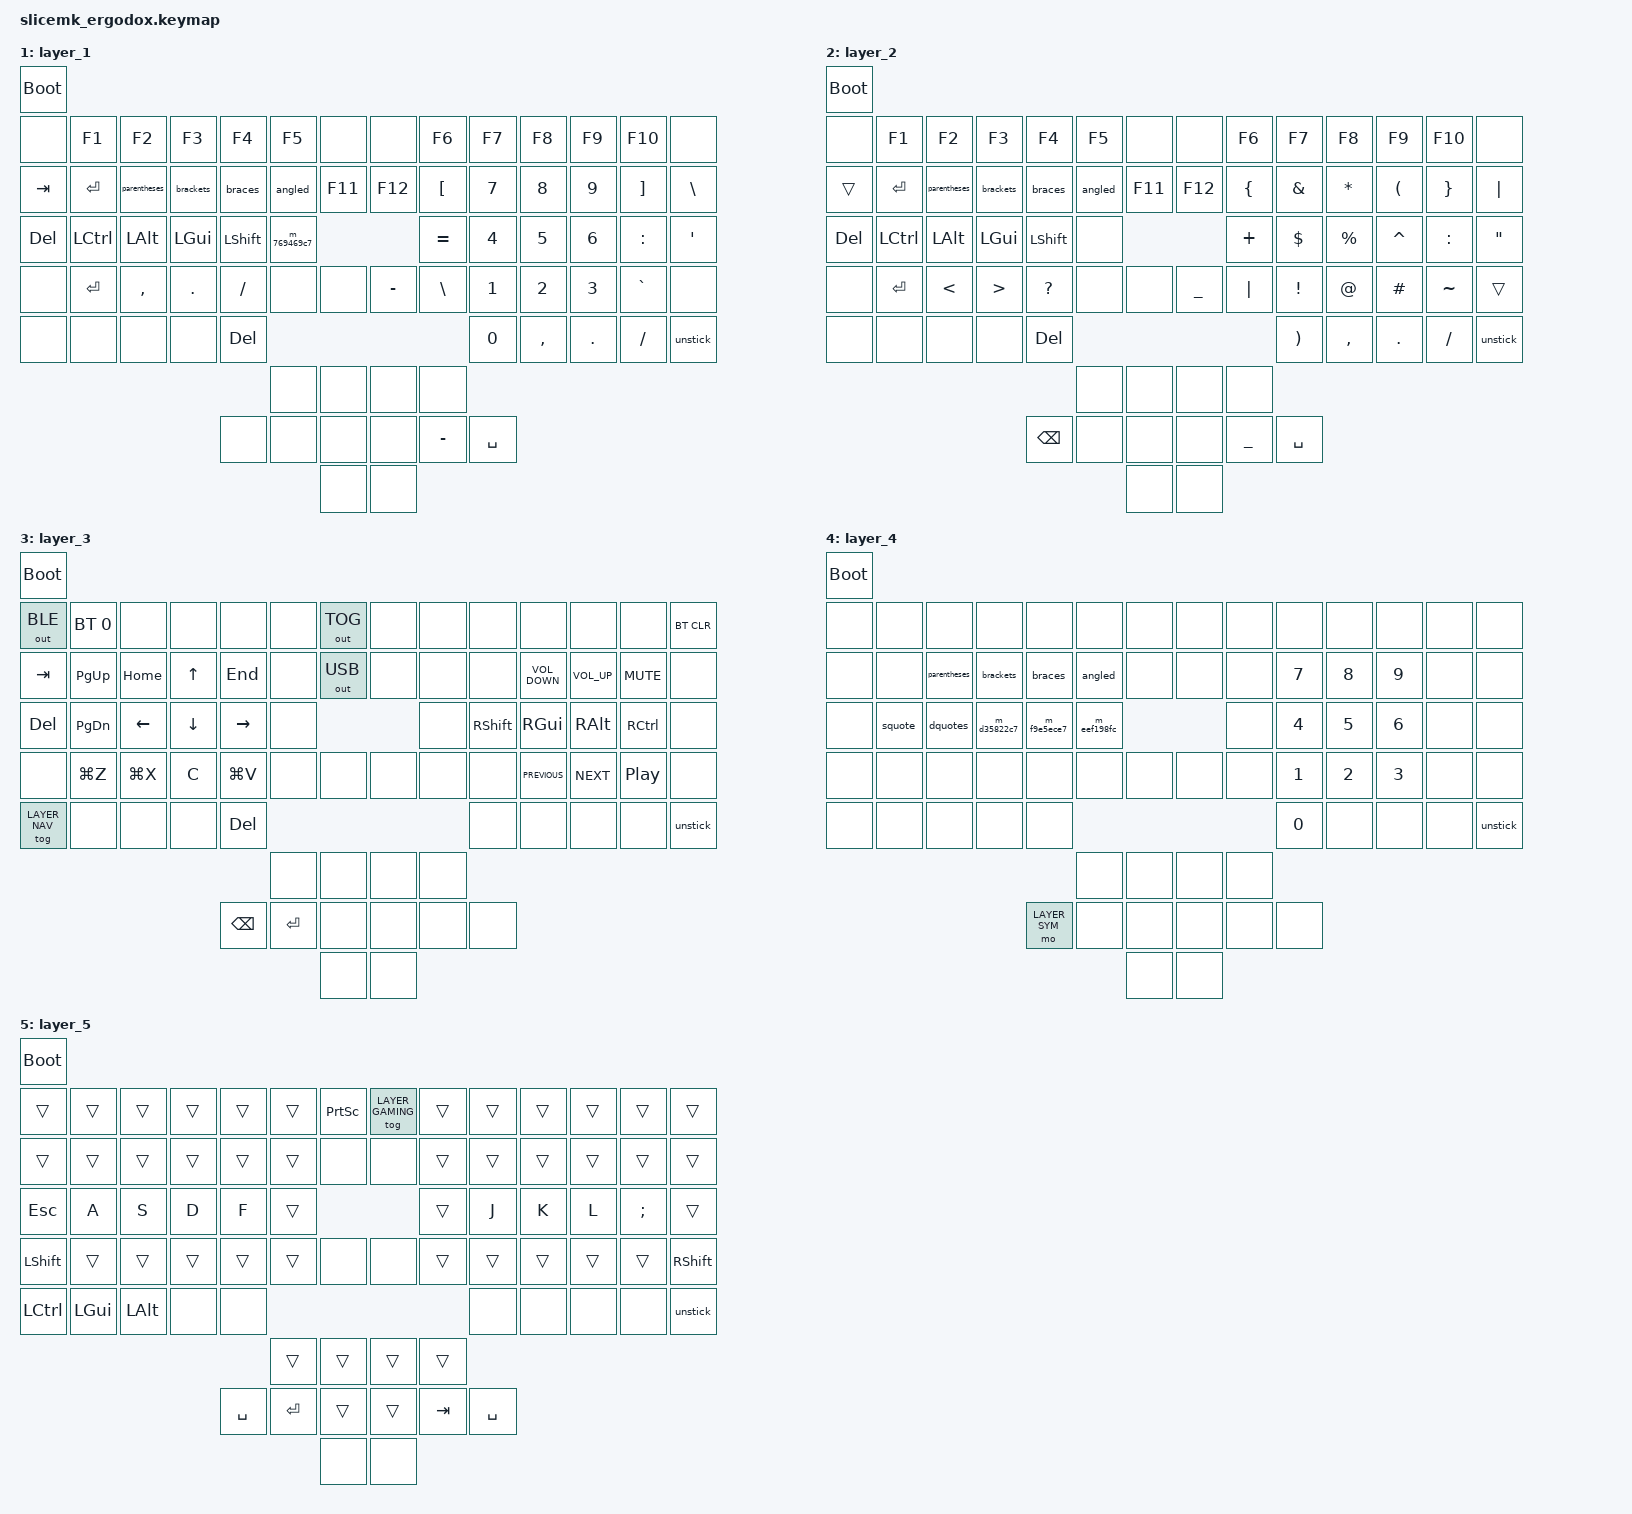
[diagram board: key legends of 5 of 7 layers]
#include <behaviors.dtsi>
#include <dt-bindings/zmk/bt.h>
#include <dt-bindings/zmk/keys.h>
#include <dt-bindings/zmk/outputs.h>
#include <dt-bindings/zmk/rgb.h>

#define LAYER_MAIN 0
#define LAYER_SYM 1
#define LAYER_SHIFTSYM 2
#define LAYER_NAV 3
#define LAYER_MACROS 4
#define LAYER_GAMING 5
#define LAYER_LINUX 6

&mt {
    tapping-term-ms = <200>;
	flavor = "tap-preferred";
	quick-tap-ms = <0>;
};

&lt {
    tapping-term-ms = <200>;
	flavor = "tap-preferred";
	quick-tap-ms = <0>;
};

&sk {
	quick-release;
};

/ {
	ZMK_MACRO(brackets, 
		wait-ms = <0>;
		tap-ms = <0>;
		bindings = <&kp LBKT &kp RBKT &kp LEFT>;
	)

	ZMK_MACRO(parentheses, 
		wait-ms = <0>;
		tap-ms = <0>;
		bindings = <&kp LPAR &kp RPAR &kp LEFT>;
	)

	ZMK_MACRO(braces, 
		wait-ms = <0>;
		tap-ms = <0>;
		bindings = <&kp LBRC &kp RBRC &kp LEFT>;
	)

	ZMK_MACRO(angled, 
		wait-ms = <0>;
		tap-ms = <0>;
		bindings = <&kp LT &kp GT &kp LEFT>;
	)

	ZMK_MACRO(squote, 
		wait-ms = <0>;
		tap-ms = <0>;
		bindings = <&kp SINGLE_QUOTE &kp SINGLE_QUOTE &kp LEFT>;
	)

	ZMK_MACRO(dquotes, 
		wait-ms = <0>;
		tap-ms = <0>;
		bindings = <&kp DOUBLE_QUOTES &kp DOUBLE_QUOTES &kp LEFT>;
	)

	ZMK_MACRO(unstick,
		wait-ms = <0>;
		tap-ms = <0>;
		bindings = <&kp LSHIFT &kp RSHIFT &kp LCTRL &kp RCTRL &kp LALT &kp RALT &kp LGUI &kp RGUI &to LAYER_MAIN>;
	)

	ZMK_MACRO(caps_macro,
		tap-ms = <200>;
		bindings = <&kp CAPS>;
	)

	sc: shift_caps {
		label = "shift caps";
		compatible = "zmk,behavior-hold-tap";
		#binding-cells = <2>;
		tapping-term-ms = <200>;
		flavor = "hold-preferred";
		bindings = <&kp>, <&caps_macro>;
	};

};


/ {
	keymap {
		compatible = "zmk,keymap";
		layer_0 {
			bindings = <
				&bootloader
				&kp GRAVE      &kp NUMBER_1       &kp NUMBER_2   &kp NUMBER_3   &kp NUMBER_4            &kp NUMBER_5              &mt LS(LG(NUMBER_4)) LS(LC(LG(NUMBER_4))) &tog LAYER_GAMING &kp NUMBER_6         &kp NUMBER_7        &kp NUMBER_8    &kp NUMBER_9     &kp NUMBER_0                &kp BACKSPACE
				&kp TAB        &kp Q              &kp W          &kp E          &kp R                   &kp T                     &kp LG(SPACE)                             &kp RC(RG(SPACE)) &kp Y                &kp U               &kp I           &kp O            &kp P                       &kp BACKSLASH
				&kp ESCAPE     &mt LEFT_CONTROL A &mt LEFT_ALT S &mt LEFT_GUI D &mt LEFT_SHIFT F        &kp G                                                                                 &kp H                &mt RIGHT_SHIFT J   &mt RIGHT_GUI K &mt RIGHT_ALT L  &mt RIGHT_CONTROL SEMICOLON &kp SINGLE_QUOTE
				&caps_word     &kp Z              &kp X          &kp C          &kp V                   &kp B                     &kp EQUAL                                 &kp MINUS         &kp N                &kp M               &kp COMMA       &kp PERIOD       &kp SLASH                   &sk RIGHT_SHIFT
				&tog LAYER_NAV &kp LG(EQUAL)      &kp LG(MINUS)  &kp LEFT_GUI   &mt LC(LEFT_ALT) DELETE                                                                                                            &kp CAPSLOCK        &none           &tog LAYER_LINUX &none                       &unstick
				                                                                                        &kp C_PREVIOUS            &kp C_NEXT                                &kp C_VOLUME_DOWN &kp C_VOLUME_UP
				                                                                &lt LAYER_SYM BACKSPACE &lt LAYER_SHIFTSYM RETURN &kp C_PLAY_PAUSE                          &kp C_MUTE        &lt LAYER_MACROS TAB &lt LAYER_NAV SPACE
				                                                                                                                  &kp SPACE                                 &tog LAYER_SYM
			>;
		};
		layer_1 {
			bindings = <
				&bootloader
				&none      &kp F1           &kp F2       &kp F3       &kp F4         &kp F5      &none   &none     &kp F6           &kp F7       &kp F8       &kp F9       &kp F10           &none
				&kp TAB    &kp RETURN       &parentheses &brackets    &braces        &angled     &kp F11 &kp F12   &kp LEFT_BRACKET &kp NUMBER_7 &kp NUMBER_8 &kp NUMBER_9 &kp RIGHT_BRACKET &kp BACKSLASH
				&kp DELETE &kp LEFT_CONTROL &kp LEFT_ALT &kp LEFT_GUI &kp LEFT_SHIFT &m_769469c7                   &kp EQUAL        &kp NUMBER_4 &kp NUMBER_5 &kp NUMBER_6 &kp COLON         &kp SINGLE_QUOTE
				&none      &kp RETURN       &kp COMMA    &kp PERIOD   &kp SLASH      &none       &none   &kp MINUS &kp BACKSLASH    &kp NUMBER_1 &kp NUMBER_2 &kp NUMBER_3 &kp GRAVE         &none
				&none      &none            &none        &none        &kp DELETE                                                    &kp NUMBER_0 &kp COMMA    &kp PERIOD   &kp SLASH         &unstick
				                                                                     &none       &none   &none     &none
				                                                      &none          &none       &none   &none     &kp MINUS        &kp SPACE
				                                                                                 &none   &none
			>;
		};
		layer_2 {
			bindings = <
				&bootloader
				&none      &kp F1           &kp F2        &kp F3           &kp F4         &kp F5  &none   &none          &kp F6         &kp F7                &kp F8       &kp F9               &kp F10         &none
				&trans     &kp RETURN       &parentheses  &brackets        &braces        &angled &kp F11 &kp F12        &kp LEFT_BRACE &kp AMPERSAND         &kp ASTERISK &kp LEFT_PARENTHESIS &kp RIGHT_BRACE &kp PIPE
				&kp DELETE &kp LEFT_CONTROL &kp LEFT_ALT  &kp LEFT_GUI     &kp LEFT_SHIFT &none                          &kp PLUS       &kp DOLLAR            &kp PERCENT  &kp CARET            &kp COLON       &kp DOUBLE_QUOTES
				&none      &kp RETURN       &kp LESS_THAN &kp GREATER_THAN &kp QUESTION   &none   &none   &kp UNDERSCORE &kp PIPE       &kp EXCLAMATION       &kp AT_SIGN  &kp HASH             &kp TILDE       &trans
				&none      &none            &none         &none            &kp DELETE                                                   &kp RIGHT_PARENTHESIS &kp COMMA    &kp PERIOD           &kp SLASH       &unstick
				                                                                          &none   &none   &none          &none
				                                                           &kp BACKSPACE  &none   &none   &none          &kp UNDERSCORE &kp SPACE
				                                                                                  &none   &none
			>;
		};
		layer_3 {
			bindings = <
				&bootloader
				&out OUT_BLE   &bt BT_SEL 0  &none          &none          &none           &none      &out OUT_TOG &none &none &none           &none             &none           &none             &bt BT_CLR
				&kp TAB        &kp PAGE_UP   &kp HOME       &kp UP_ARROW   &kp END         &none      &out OUT_USB &none &none &none           &kp C_VOLUME_DOWN &kp C_VOLUME_UP &kp C_MUTE        &none
				&kp DELETE     &kp PAGE_DOWN &kp LEFT_ARROW &kp DOWN_ARROW &kp RIGHT_ARROW &none                         &none &kp RIGHT_SHIFT &kp RIGHT_GUI     &kp RIGHT_ALT   &kp RIGHT_CONTROL &none
				&none          &kp LG(Z)     &kp LG(X)      &kp C          &kp LG(V)       &none      &none        &none &none &none           &kp C_PREVIOUS    &kp C_NEXT      &kp C_PLAY_PAUSE  &none
				&tog LAYER_NAV &none         &none          &none          &kp DELETE                                          &none           &none             &none           &none             &unstick
				                                                                           &none      &none        &none &none
				                                                           &kp BACKSPACE   &kp RETURN &none        &none &none &none
				                                                                                      &none        &none
			>;
		};
		layer_4 {
			bindings = <
				&bootloader
				&none &none   &none        &none       &none         &none       &none &none &none &none        &none        &none        &none &none
				&none &none   &parentheses &brackets   &braces       &angled     &none &none &none &kp NUMBER_7 &kp NUMBER_8 &kp NUMBER_9 &none &none
				&none &squote &dquotes     &m_d35822c7 &m_f9e5ece7   &m_eef198fc             &none &kp NUMBER_4 &kp NUMBER_5 &kp NUMBER_6 &none &none
				&none &none   &none        &none       &none         &none       &none &none &none &kp NUMBER_1 &kp NUMBER_2 &kp NUMBER_3 &none &none
				&none &none   &none        &none       &none                                       &kp NUMBER_0 &none        &none        &none &unstick
				                                                     &none       &none &none &none
				                                       &mo LAYER_SYM &none       &none &none &none &none
				                                                                 &none &none
			>;
		};
		layer_5 {
			bindings = <
				&bootloader
				&trans           &trans       &trans       &trans &trans    &trans     &kp PRINTSCREEN &tog LAYER_GAMING &trans  &trans    &trans &trans &trans        &trans
				&trans           &trans       &trans       &trans &trans    &trans     &none           &none             &trans  &trans    &trans &trans &trans        &trans
				&kp ESCAPE       &kp A        &kp S        &kp D  &kp F     &trans                                       &trans  &kp J     &kp K  &kp L  &kp SEMICOLON &trans
				&kp LEFT_SHIFT   &trans       &trans       &trans &trans    &trans     &none           &none             &trans  &trans    &trans &trans &trans        &kp RIGHT_SHIFT
				&kp LEFT_CONTROL &kp LEFT_GUI &kp LEFT_ALT &none  &none                                                          &none     &none  &none  &none         &unstick
				                                                            &trans     &trans          &trans            &trans
				                                                  &kp SPACE &kp RETURN &trans          &trans            &kp TAB &kp SPACE
				                                                                       &none           &none
			>;
		};
		layer_6 {
			bindings = <
				&bootloader
				&kp GRAVE      &kp NUMBER_1   &kp NUMBER_2   &kp NUMBER_3       &kp NUMBER_4            &kp NUMBER_5              &kp LS(LG(PRINTSCREEN)) &tog LAYER_GAMING &kp NUMBER_6          &kp NUMBER_7        &kp NUMBER_8        &kp NUMBER_9    &kp NUMBER_0            &kp BACKSPACE
				&kp TAB        &kp Q          &kp W          &kp E              &kp R                   &kp T                     &none                   &none             &kp Y                 &kp U               &kp I               &kp O           &kp P                   &kp BACKSLASH
				&kp ESCAPE     &mt LEFT_GUI A &mt LEFT_ALT S &mt LEFT_CONTROL D &mt LEFT_SHIFT F        &kp G                                                               &kp H                 &mt RIGHT_SHIFT J   &mt RIGHT_CONTROL K &mt RIGHT_ALT L &mt RIGHT_GUI SEMICOLON &kp SINGLE_QUOTE
				&caps_word     &kp Z          &kp X          &kp C              &kp V                   &kp B                     &kp EQUAL               &kp MINUS         &kp N                 &kp M               &kp COMMA           &kp PERIOD      &kp SLASH               &sc RIGHT_SHIFT &caps_macro
				&tog LAYER_NAV &none          &none          &kp LEFT_GUI       &mt LC(LEFT_ALT) DELETE                                                                                           &kp CAPSLOCK        &none               &none           &none                   &unstick
				                                                                                        &kp C_PREVIOUS            &kp C_NEXT              &kp C_VOLUME_DOWN &kp C_VOLUME_UP
				                                                                &lt LAYER_SYM BACKSPACE &lt LAYER_SHIFTSYM RETURN &kp C_PLAY_PAUSE        &kp C_MUTE        &mt RC(RIGHT_ALT) TAB &lt LAYER_NAV SPACE
				                                                                                                                  &kp SPACE               &tog LAYER_SYM
			>;
		};
	};

	ZMK_MACRO(m_769469c7, wait-ms = <10>; tap-ms = <10>; bindings = <&macro_tap &kp MINUS>, <&macro_tap &kp GREATER_THAN>;)
	ZMK_MACRO(m_d35822c7, wait-ms = <10>; tap-ms = <10>; bindings = <&macro_tap &kp SPACE>, <&macro_tap &kp PLUS>, <&macro_tap &kp EQUAL>, <&macro_tap &kp SPACE>;)
	ZMK_MACRO(m_f9e5ece7, wait-ms = <10>; tap-ms = <10>; bindings = <&macro_tap &kp SPACE>, <&macro_tap &kp MINUS>, <&macro_tap &kp EQUAL>, <&macro_tap &kp SPACE>;)
	ZMK_MACRO(m_eef198fc, wait-ms = <10>; tap-ms = <10>; bindings = <&macro_tap &kp MINUS>, <&macro_tap &kp GREATER_THAN>;)
};
